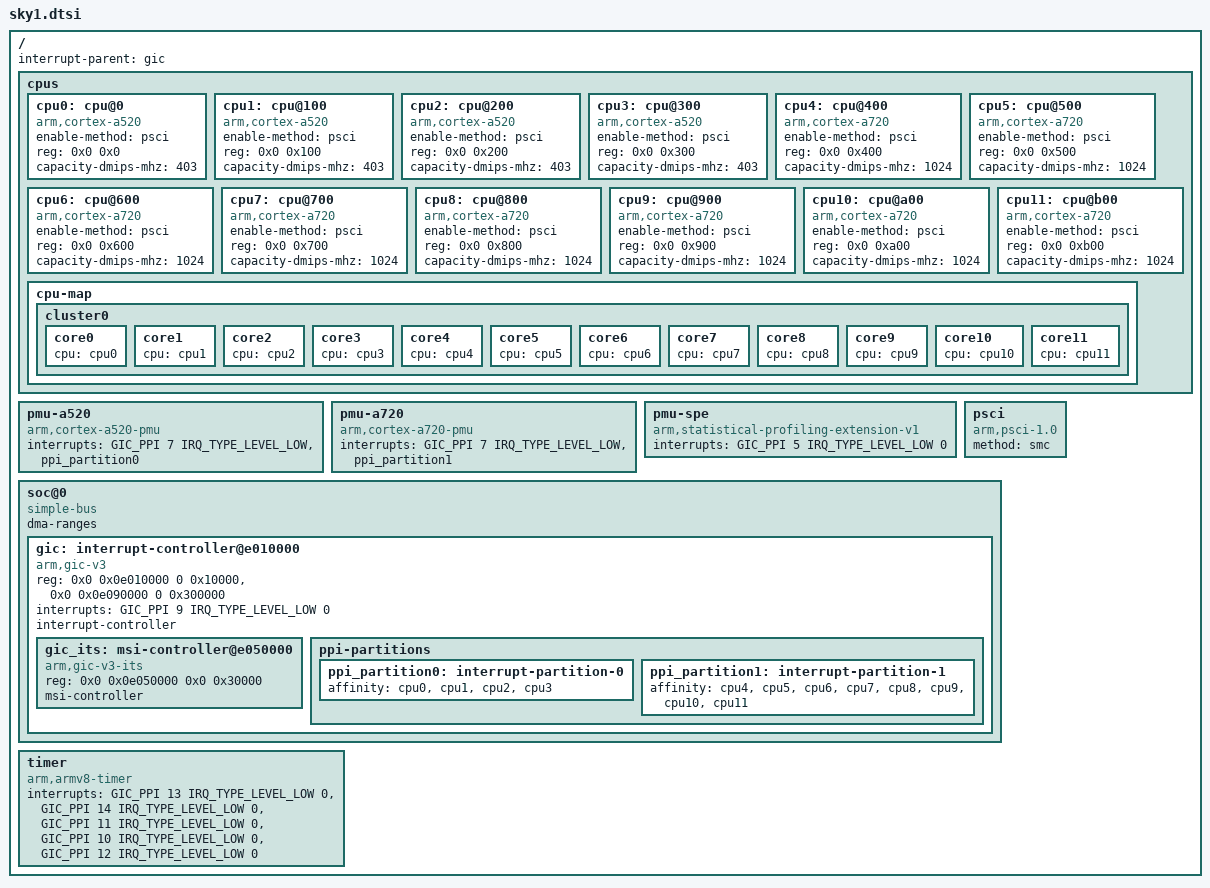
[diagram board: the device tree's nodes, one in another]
// SPDX-License-Identifier: BSD-3-Clause
/*
 * Copyright 2025 Cix Technology Group Co., Ltd.
 *
 */

#include <dt-bindings/interrupt-controller/arm-gic.h>

/ {
	interrupt-parent = <&gic>;
	#address-cells = <2>;
	#size-cells = <2>;

	cpus {
		#address-cells = <2>;
		#size-cells = <0>;

		cpu0: cpu@0 {
			compatible = "arm,cortex-a520";
			enable-method = "psci";
			reg = <0x0 0x0>;
			device_type = "cpu";
			capacity-dmips-mhz = <403>;
		};

		cpu1: cpu@100 {
			compatible = "arm,cortex-a520";
			enable-method = "psci";
			reg = <0x0 0x100>;
			device_type = "cpu";
			capacity-dmips-mhz = <403>;
		};

		cpu2: cpu@200 {
			compatible = "arm,cortex-a520";
			enable-method = "psci";
			reg = <0x0 0x200>;
			device_type = "cpu";
			capacity-dmips-mhz = <403>;
		};

		cpu3: cpu@300 {
			compatible = "arm,cortex-a520";
			enable-method = "psci";
			reg = <0x0 0x300>;
			device_type = "cpu";
			capacity-dmips-mhz = <403>;
		};

		cpu4: cpu@400 {
			compatible = "arm,cortex-a720";
			enable-method = "psci";
			reg = <0x0 0x400>;
			device_type = "cpu";
			capacity-dmips-mhz = <1024>;
		};

		cpu5: cpu@500 {
			compatible = "arm,cortex-a720";
			enable-method = "psci";
			reg = <0x0 0x500>;
			device_type = "cpu";
			capacity-dmips-mhz = <1024>;
		};

		cpu6: cpu@600 {
			compatible = "arm,cortex-a720";
			enable-method = "psci";
			reg = <0x0 0x600>;
			device_type = "cpu";
			capacity-dmips-mhz = <1024>;
		};

		cpu7: cpu@700 {
			compatible = "arm,cortex-a720";
			enable-method = "psci";
			reg = <0x0 0x700>;
			device_type = "cpu";
			capacity-dmips-mhz = <1024>;
		};

		cpu8: cpu@800 {
			compatible = "arm,cortex-a720";
			enable-method = "psci";
			reg = <0x0 0x800>;
			device_type = "cpu";
			capacity-dmips-mhz = <1024>;
		};

		cpu9: cpu@900 {
			compatible = "arm,cortex-a720";
			enable-method = "psci";
			reg = <0x0 0x900>;
			device_type = "cpu";
			capacity-dmips-mhz = <1024>;
		};

		cpu10: cpu@a00 {
			compatible = "arm,cortex-a720";
			enable-method = "psci";
			reg = <0x0 0xa00>;
			device_type = "cpu";
			capacity-dmips-mhz = <1024>;
		};

		cpu11: cpu@b00 {
			compatible = "arm,cortex-a720";
			enable-method = "psci";
			reg = <0x0 0xb00>;
			device_type = "cpu";
			capacity-dmips-mhz = <1024>;
		};

		cpu-map {
			cluster0 {
				core0 {
					cpu = <&cpu0>;
				};
				core1 {
					cpu = <&cpu1>;
				};
				core2 {
					cpu = <&cpu2>;
				};
				core3 {
					cpu = <&cpu3>;
				};
				core4 {
					cpu = <&cpu4>;
				};
				core5 {
					cpu = <&cpu5>;
				};
				core6 {
					cpu = <&cpu6>;
				};
				core7 {
					cpu = <&cpu7>;
				};
				core8 {
					cpu = <&cpu8>;
				};
				core9 {
					cpu = <&cpu9>;
				};
				core10 {
					cpu = <&cpu10>;
				};
				core11 {
					cpu = <&cpu11>;
				};
			};
		};
	};

	pmu-a520 {
		compatible = "arm,cortex-a520-pmu";
		interrupts = <GIC_PPI 7 IRQ_TYPE_LEVEL_LOW &ppi_partition0>;
	};

	pmu-a720 {
		compatible = "arm,cortex-a720-pmu";
		interrupts = <GIC_PPI 7 IRQ_TYPE_LEVEL_LOW &ppi_partition1>;
	};

	pmu-spe {
		compatible = "arm,statistical-profiling-extension-v1";
		interrupts = <GIC_PPI 5 IRQ_TYPE_LEVEL_LOW 0>;
	};

	psci {
		compatible = "arm,psci-1.0";
		method = "smc";
	};

	soc@0 {
		compatible = "simple-bus";
		ranges = <0 0 0 0 0x20 0>;
		dma-ranges;
		#address-cells = <2>;
		#size-cells = <2>;

		gic: interrupt-controller@e010000 {
			compatible = "arm,gic-v3";
			reg = <0x0 0x0e010000 0 0x10000>,	/* GICD */
			      <0x0 0x0e090000 0 0x300000>;       /* GICR * 12 */
			interrupts = <GIC_PPI 9 IRQ_TYPE_LEVEL_LOW 0>;
			#interrupt-cells = <4>;
			interrupt-controller;
			#address-cells = <2>;
			#size-cells = <2>;
			ranges;

			gic_its: msi-controller@e050000 {
				compatible = "arm,gic-v3-its";
				reg = <0x0 0x0e050000 0x0 0x30000>;
				msi-controller;
				#msi-cells = <1>;
			};

			ppi-partitions {
				ppi_partition0: interrupt-partition-0 {
					affinity = <&cpu0 &cpu1 &cpu2 &cpu3>;
				};

				ppi_partition1: interrupt-partition-1 {
					affinity = <&cpu4 &cpu5 &cpu6 &cpu7 &cpu8 &cpu9 &cpu10 &cpu11>;
				};
			};
		};
	};

	timer {
		compatible = "arm,armv8-timer";
		interrupt-names = "sec-phys", "phys", "virt", "hyp-phys", "hyp-virt";
		interrupts = <GIC_PPI 13 IRQ_TYPE_LEVEL_LOW 0>,
			     <GIC_PPI 14 IRQ_TYPE_LEVEL_LOW 0>,
			     <GIC_PPI 11 IRQ_TYPE_LEVEL_LOW 0>,
			     <GIC_PPI 10 IRQ_TYPE_LEVEL_LOW 0>,
			     <GIC_PPI 12 IRQ_TYPE_LEVEL_LOW 0>;
	};
};
